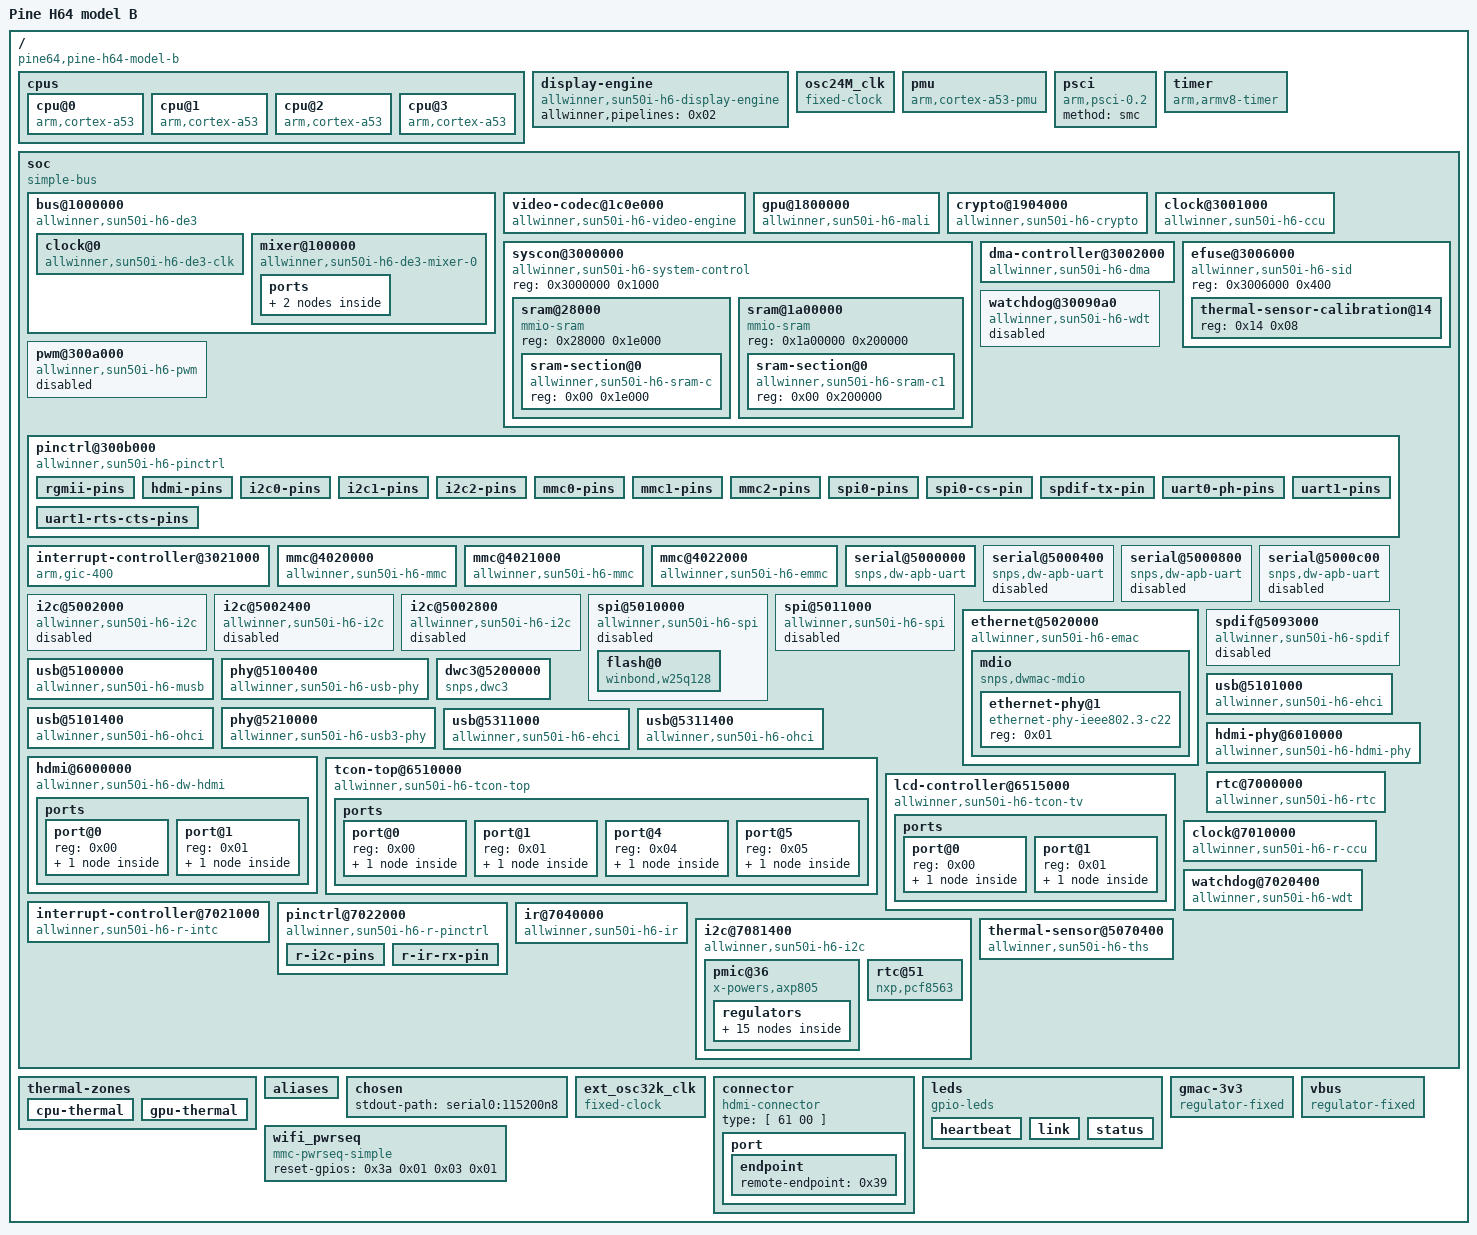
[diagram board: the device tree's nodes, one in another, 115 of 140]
/dts-v1/;

/ {
	interrupt-parent = < 0x01 >;
	#address-cells = < 0x01 >;
	#size-cells = < 0x01 >;
	model = "Pine H64 model B";
	compatible = "pine64,pine-h64-model-b\0allwinner,sun50i-h6";

	cpus {
		#address-cells = < 0x01 >;
		#size-cells = < 0x00 >;

		cpu@0 {
			compatible = "arm,cortex-a53";
			device_type = "cpu";
			reg = < 0x00 >;
			enable-method = "psci";
			phandle = < 0x03 >;
		};

		cpu@1 {
			compatible = "arm,cortex-a53";
			device_type = "cpu";
			reg = < 0x01 >;
			enable-method = "psci";
			phandle = < 0x04 >;
		};

		cpu@2 {
			compatible = "arm,cortex-a53";
			device_type = "cpu";
			reg = < 0x02 >;
			enable-method = "psci";
			phandle = < 0x05 >;
		};

		cpu@3 {
			compatible = "arm,cortex-a53";
			device_type = "cpu";
			reg = < 0x03 >;
			enable-method = "psci";
			phandle = < 0x06 >;
		};
	};

	display-engine {
		compatible = "allwinner,sun50i-h6-display-engine";
		allwinner,pipelines = < 0x02 >;
		status = "okay";
	};

	osc24M_clk {
		#clock-cells = < 0x00 >;
		compatible = "fixed-clock";
		clock-frequency = < 0x16e3600 >;
		clock-output-names = "osc24M";
		phandle = < 0x0d >;
	};

	pmu {
		compatible = "arm,cortex-a53-pmu";
		interrupts = < 0x00 0x8c 0x04 0x00 0x8d 0x04 0x00 0x8e 0x04 0x00 0x8f 0x04 >;
		interrupt-affinity = < 0x03 0x04 0x05 0x06 >;
	};

	psci {
		compatible = "arm,psci-0.2";
		method = "smc";
	};

	timer {
		compatible = "arm,armv8-timer";
		interrupts = < 0x01 0x0d 0xf04 0x01 0x0e 0xf04 0x01 0x0b 0xf04 0x01 0x0a 0xf04 >;
	};

	soc {
		compatible = "simple-bus";
		#address-cells = < 0x01 >;
		#size-cells = < 0x01 >;
		ranges;

		bus@1000000 {
			compatible = "allwinner,sun50i-h6-de3\0allwinner,sun50i-a64-de2";
			reg = < 0x1000000 0x400000 >;
			allwinner,sram = < 0x07 0x01 >;
			#address-cells = < 0x01 >;
			#size-cells = < 0x01 >;
			ranges = < 0x00 0x1000000 0x400000 >;

			clock@0 {
				compatible = "allwinner,sun50i-h6-de3-clk";
				reg = < 0x00 0x10000 >;
				clocks = < 0x08 0x1d 0x08 0x1e >;
				clock-names = "mod\0bus";
				resets = < 0x08 0x01 >;
				#clock-cells = < 0x01 >;
				#reset-cells = < 0x01 >;
				phandle = < 0x09 >;
			};

			mixer@100000 {
				compatible = "allwinner,sun50i-h6-de3-mixer-0";
				reg = < 0x100000 0x100000 >;
				clocks = < 0x09 0x00 0x09 0x06 >;
				clock-names = "bus\0mod";
				resets = < 0x09 0x00 >;
				phandle = < 0x02 >;

				ports {
					#address-cells = < 0x01 >;
					#size-cells = < 0x00 >;

					port@1 {
						reg = < 0x01 >;

						endpoint {
							remote-endpoint = < 0x0a >;
							phandle = < 0x2b >;
						};
					};
				};
			};
		};

		video-codec@1c0e000 {
			compatible = "allwinner,sun50i-h6-video-engine";
			reg = < 0x1c0e000 0x2000 >;
			clocks = < 0x08 0x26 0x08 0x25 0x08 0x36 >;
			clock-names = "ahb\0mod\0ram";
			resets = < 0x08 0x05 >;
			interrupts = < 0x00 0x59 0x04 >;
			allwinner,sram = < 0x0b 0x01 >;
		};

		gpu@1800000 {
			compatible = "allwinner,sun50i-h6-mali\0arm,mali-t720";
			reg = < 0x1800000 0x4000 >;
			interrupts = < 0x00 0x54 0x04 0x00 0x55 0x04 0x00 0x53 0x04 >;
			interrupt-names = "job\0mmu\0gpu";
			clocks = < 0x08 0x21 0x08 0x22 >;
			clock-names = "core\0bus";
			resets = < 0x08 0x03 >;
			status = "okay";
			mali-supply = < 0x0c >;
		};

		crypto@1904000 {
			compatible = "allwinner,sun50i-h6-crypto";
			reg = < 0x1904000 0x1000 >;
			interrupts = < 0x00 0x57 0x04 >;
			clocks = < 0x08 0x24 0x08 0x23 0x08 0x37 >;
			clock-names = "bus\0mod\0ram";
			resets = < 0x08 0x04 >;
		};

		syscon@3000000 {
			compatible = "allwinner,sun50i-h6-system-control\0allwinner,sun50i-a64-system-control";
			reg = < 0x3000000 0x1000 >;
			#address-cells = < 0x01 >;
			#size-cells = < 0x01 >;
			ranges;
			phandle = < 0x1f >;

			sram@28000 {
				compatible = "mmio-sram";
				reg = < 0x28000 0x1e000 >;
				#address-cells = < 0x01 >;
				#size-cells = < 0x01 >;
				ranges = < 0x00 0x28000 0x1e000 >;

				sram-section@0 {
					compatible = "allwinner,sun50i-h6-sram-c\0allwinner,sun50i-a64-sram-c";
					reg = < 0x00 0x1e000 >;
					phandle = < 0x07 >;
				};
			};

			sram@1a00000 {
				compatible = "mmio-sram";
				reg = < 0x1a00000 0x200000 >;
				#address-cells = < 0x01 >;
				#size-cells = < 0x01 >;
				ranges = < 0x00 0x1a00000 0x200000 >;

				sram-section@0 {
					compatible = "allwinner,sun50i-h6-sram-c1\0allwinner,sun4i-a10-sram-c1";
					reg = < 0x00 0x200000 >;
					phandle = < 0x0b >;
				};
			};
		};

		clock@3001000 {
			compatible = "allwinner,sun50i-h6-ccu";
			reg = < 0x3001000 0x1000 >;
			clocks = < 0x0d 0x0e 0x00 0x0e 0x02 >;
			clock-names = "hosc\0losc\0iosc";
			#clock-cells = < 0x01 >;
			#reset-cells = < 0x01 >;
			phandle = < 0x08 >;
		};

		dma-controller@3002000 {
			compatible = "allwinner,sun50i-h6-dma";
			reg = < 0x3002000 0x1000 >;
			interrupts = < 0x00 0x2b 0x04 >;
			clocks = < 0x08 0x2b 0x08 0x35 >;
			clock-names = "bus\0mbus";
			dma-channels = < 0x10 >;
			dma-requests = < 0x2e >;
			resets = < 0x08 0x08 >;
			#dma-cells = < 0x01 >;
			phandle = < 0x1c >;
		};

		efuse@3006000 {
			compatible = "allwinner,sun50i-h6-sid";
			reg = < 0x3006000 0x400 >;
			#address-cells = < 0x01 >;
			#size-cells = < 0x01 >;

			thermal-sensor-calibration@14 {
				reg = < 0x14 0x08 >;
				phandle = < 0x37 >;
			};
		};

		watchdog@30090a0 {
			compatible = "allwinner,sun50i-h6-wdt\0allwinner,sun6i-a31-wdt";
			reg = < 0x30090a0 0x20 >;
			interrupts = < 0x00 0x32 0x04 >;
			clocks = < 0x0d >;
			status = "disabled";
		};

		pwm@300a000 {
			compatible = "allwinner,sun50i-h6-pwm";
			reg = < 0x300a000 0x400 >;
			clocks = < 0x0d 0x08 0x32 >;
			clock-names = "mod\0bus";
			resets = < 0x08 0x0e >;
			#pwm-cells = < 0x03 >;
			status = "disabled";
		};

		pinctrl@300b000 {
			compatible = "allwinner,sun50i-h6-pinctrl";
			reg = < 0x300b000 0x400 >;
			interrupts = < 0x00 0x33 0x04 0x00 0x35 0x04 0x00 0x36 0x04 0x00 0x3b 0x04 >;
			clocks = < 0x08 0x1a 0x0d 0x0e 0x00 >;
			clock-names = "apb\0hosc\0losc";
			gpio-controller;
			#gpio-cells = < 0x03 >;
			interrupt-controller;
			#interrupt-cells = < 0x03 >;
			vcc-pc-supply = < 0x0f >;
			vcc-pd-supply = < 0x10 >;
			vcc-pg-supply = < 0x11 >;
			phandle = < 0x13 >;

			rgmii-pins {
				pins = "PD0\0PD1\0PD2\0PD3\0PD4\0PD5\0PD7\0PD8\0PD9\0PD10\0PD11\0PD12\0PD13\0PD19\0PD20";
				function = "emac";
				drive-strength = < 0x28 >;
				phandle = < 0x20 >;
			};

			hdmi-pins {
				pins = "PH8\0PH9\0PH10";
				function = "hdmi";
				phandle = < 0x28 >;
			};

			i2c0-pins {
				pins = "PD25\0PD26";
				function = "i2c0";
				phandle = < 0x19 >;
			};

			i2c1-pins {
				pins = "PH5\0PH6";
				function = "i2c1";
				phandle = < 0x1a >;
			};

			i2c2-pins {
				pins = "PD23\0PD24";
				function = "i2c2";
				phandle = < 0x1b >;
			};

			mmc0-pins {
				pins = "PF0\0PF1\0PF2\0PF3\0PF4\0PF5";
				function = "mmc0";
				drive-strength = < 0x1e >;
				bias-pull-up;
				phandle = < 0x12 >;
			};

			mmc1-pins {
				pins = "PG0\0PG1\0PG2\0PG3\0PG4\0PG5";
				function = "mmc1";
				drive-strength = < 0x1e >;
				bias-pull-up;
				phandle = < 0x14 >;
			};

			mmc2-pins {
				pins = "PC1\0PC4\0PC5\0PC6\0PC7\0PC8\0PC9\0PC10\0PC11\0PC12\0PC13\0PC14";
				function = "mmc2";
				drive-strength = < 0x1e >;
				bias-pull-up;
				phandle = < 0x17 >;
			};

			spi0-pins {
				pins = "PC0\0PC2\0PC3";
				function = "spi0";
				phandle = < 0x1d >;
			};

			spi0-cs-pin {
				pins = "PC5";
				function = "spi0";
				phandle = < 0x1e >;
			};

			spdif-tx-pin {
				pins = "PH7";
				function = "spdif";
				phandle = < 0x23 >;
			};

			uart0-ph-pins {
				pins = "PH0\0PH1";
				function = "uart0";
				phandle = < 0x18 >;
			};

			uart1-pins {
				pins = "PG6\0PG7";
				function = "uart1";
			};

			uart1-rts-cts-pins {
				pins = "PG8\0PG9";
				function = "uart1";
			};
		};

		interrupt-controller@3021000 {
			compatible = "arm,gic-400";
			reg = < 0x3021000 0x1000 0x3022000 0x2000 0x3024000 0x2000 0x3026000 0x2000 >;
			interrupts = < 0x01 0x09 0xf04 >;
			interrupt-controller;
			#interrupt-cells = < 0x03 >;
			phandle = < 0x01 >;
		};

		mmc@4020000 {
			compatible = "allwinner,sun50i-h6-mmc\0allwinner,sun50i-a64-mmc";
			reg = < 0x4020000 0x1000 >;
			clocks = < 0x08 0x43 0x08 0x40 >;
			clock-names = "ahb\0mmc";
			resets = < 0x08 0x12 >;
			reset-names = "ahb";
			interrupts = < 0x00 0x23 0x04 >;
			pinctrl-names = "default";
			pinctrl-0 = < 0x12 >;
			status = "okay";
			#address-cells = < 0x01 >;
			#size-cells = < 0x00 >;
			vmmc-supply = < 0x10 >;
			cd-gpios = < 0x13 0x05 0x06 0x01 >;
			bus-width = < 0x04 >;
		};

		mmc@4021000 {
			compatible = "allwinner,sun50i-h6-mmc\0allwinner,sun50i-a64-mmc";
			reg = < 0x4021000 0x1000 >;
			clocks = < 0x08 0x44 0x08 0x41 >;
			clock-names = "ahb\0mmc";
			resets = < 0x08 0x13 >;
			reset-names = "ahb";
			interrupts = < 0x00 0x24 0x04 >;
			pinctrl-names = "default";
			pinctrl-0 = < 0x14 >;
			status = "okay";
			#address-cells = < 0x01 >;
			#size-cells = < 0x00 >;
			vmmc-supply = < 0x15 >;
			vqmmc-supply = < 0x0f >;
			mmc-pwrseq = < 0x16 >;
			non-removable;
			bus-width = < 0x04 >;
		};

		mmc@4022000 {
			compatible = "allwinner,sun50i-h6-emmc\0allwinner,sun50i-a64-emmc";
			reg = < 0x4022000 0x1000 >;
			clocks = < 0x08 0x45 0x08 0x42 >;
			clock-names = "ahb\0mmc";
			resets = < 0x08 0x14 >;
			reset-names = "ahb";
			interrupts = < 0x00 0x25 0x04 >;
			pinctrl-names = "default";
			pinctrl-0 = < 0x17 >;
			mmc-hs200-1_8v;
			mmc-hs400-1_8v;
			mmc-hs400-enhanced-strobe;
			status = "okay";
			#address-cells = < 0x01 >;
			#size-cells = < 0x00 >;
			vmmc-supply = < 0x10 >;
			vqmmc-supply = < 0x0f >;
			non-removable;
			cap-mmc-hw-reset;
			bus-width = < 0x08 >;
		};

		serial@5000000 {
			compatible = "snps,dw-apb-uart";
			reg = < 0x5000000 0x400 >;
			interrupts = < 0x00 0x00 0x04 >;
			reg-shift = < 0x02 >;
			reg-io-width = < 0x04 >;
			clocks = < 0x08 0x46 >;
			resets = < 0x08 0x15 >;
			status = "okay";
			pinctrl-names = "default";
			pinctrl-0 = < 0x18 >;
		};

		serial@5000400 {
			compatible = "snps,dw-apb-uart";
			reg = < 0x5000400 0x400 >;
			interrupts = < 0x00 0x01 0x04 >;
			reg-shift = < 0x02 >;
			reg-io-width = < 0x04 >;
			clocks = < 0x08 0x47 >;
			resets = < 0x08 0x16 >;
			status = "disabled";
		};

		serial@5000800 {
			compatible = "snps,dw-apb-uart";
			reg = < 0x5000800 0x400 >;
			interrupts = < 0x00 0x02 0x04 >;
			reg-shift = < 0x02 >;
			reg-io-width = < 0x04 >;
			clocks = < 0x08 0x48 >;
			resets = < 0x08 0x17 >;
			status = "disabled";
		};

		serial@5000c00 {
			compatible = "snps,dw-apb-uart";
			reg = < 0x5000c00 0x400 >;
			interrupts = < 0x00 0x03 0x04 >;
			reg-shift = < 0x02 >;
			reg-io-width = < 0x04 >;
			clocks = < 0x08 0x49 >;
			resets = < 0x08 0x18 >;
			status = "disabled";
		};

		i2c@5002000 {
			compatible = "allwinner,sun50i-h6-i2c\0allwinner,sun6i-a31-i2c";
			reg = < 0x5002000 0x400 >;
			interrupts = < 0x00 0x04 0x04 >;
			clocks = < 0x08 0x4a >;
			resets = < 0x08 0x19 >;
			pinctrl-names = "default";
			pinctrl-0 = < 0x19 >;
			status = "disabled";
			#address-cells = < 0x01 >;
			#size-cells = < 0x00 >;
		};

		i2c@5002400 {
			compatible = "allwinner,sun50i-h6-i2c\0allwinner,sun6i-a31-i2c";
			reg = < 0x5002400 0x400 >;
			interrupts = < 0x00 0x05 0x04 >;
			clocks = < 0x08 0x4b >;
			resets = < 0x08 0x1a >;
			pinctrl-names = "default";
			pinctrl-0 = < 0x1a >;
			status = "disabled";
			#address-cells = < 0x01 >;
			#size-cells = < 0x00 >;
		};

		i2c@5002800 {
			compatible = "allwinner,sun50i-h6-i2c\0allwinner,sun6i-a31-i2c";
			reg = < 0x5002800 0x400 >;
			interrupts = < 0x00 0x06 0x04 >;
			clocks = < 0x08 0x4c >;
			resets = < 0x08 0x1b >;
			pinctrl-names = "default";
			pinctrl-0 = < 0x1b >;
			status = "disabled";
			#address-cells = < 0x01 >;
			#size-cells = < 0x00 >;
		};

		spi@5010000 {
			compatible = "allwinner,sun50i-h6-spi\0allwinner,sun8i-h3-spi";
			reg = < 0x5010000 0x1000 >;
			interrupts = < 0x00 0x0a 0x04 >;
			clocks = < 0x08 0x52 0x08 0x50 >;
			clock-names = "ahb\0mod";
			dmas = < 0x1c 0x16 0x1c 0x16 >;
			dma-names = "rx\0tx";
			resets = < 0x08 0x1f >;
			status = "disabled";
			#address-cells = < 0x01 >;
			#size-cells = < 0x00 >;
			pinctrl-0 = < 0x1d 0x1e >;
			pinctrl-names = "default";

			flash@0 {
				compatible = "winbond,w25q128\0jedec,spi-nor";
				reg = < 0x00 >;
				spi-max-frequency = < 0x3d0900 >;
			};
		};

		spi@5011000 {
			compatible = "allwinner,sun50i-h6-spi\0allwinner,sun8i-h3-spi";
			reg = < 0x5011000 0x1000 >;
			interrupts = < 0x00 0x0b 0x04 >;
			clocks = < 0x08 0x53 0x08 0x51 >;
			clock-names = "ahb\0mod";
			dmas = < 0x1c 0x17 0x1c 0x17 >;
			dma-names = "rx\0tx";
			resets = < 0x08 0x20 >;
			status = "disabled";
			#address-cells = < 0x01 >;
			#size-cells = < 0x00 >;
		};

		ethernet@5020000 {
			compatible = "allwinner,sun50i-h6-emac\0allwinner,sun50i-a64-emac";
			syscon = < 0x1f >;
			reg = < 0x5020000 0x10000 >;
			interrupts = < 0x00 0x0c 0x04 >;
			interrupt-names = "macirq";
			resets = < 0x08 0x21 >;
			reset-names = "stmmaceth";
			clocks = < 0x08 0x54 >;
			clock-names = "stmmaceth";
			status = "okay";
			pinctrl-names = "default";
			pinctrl-0 = < 0x20 >;
			phy-mode = "rgmii";
			phy-handle = < 0x21 >;
			phy-supply = < 0x22 >;
			allwinner,rx-delay-ps = < 0xc8 >;
			allwinner,tx-delay-ps = < 0xc8 >;

			mdio {
				compatible = "snps,dwmac-mdio";
				#address-cells = < 0x01 >;
				#size-cells = < 0x00 >;

				ethernet-phy@1 {
					compatible = "ethernet-phy-ieee802.3-c22";
					reg = < 0x01 >;
					phandle = < 0x21 >;
				};
			};
		};

		spdif@5093000 {
			#sound-dai-cells = < 0x00 >;
			compatible = "allwinner,sun50i-h6-spdif";
			reg = < 0x5093000 0x400 >;
			interrupts = < 0x00 0x15 0x04 >;
			clocks = < 0x08 0x63 0x08 0x62 >;
			clock-names = "apb\0spdif";
			resets = < 0x08 0x29 >;
			dmas = < 0x1c 0x02 >;
			dma-names = "tx";
			pinctrl-names = "default";
			pinctrl-0 = < 0x23 >;
			status = "disabled";
		};

		usb@5100000 {
			compatible = "allwinner,sun50i-h6-musb\0allwinner,sun8i-a33-musb";
			reg = < 0x5100000 0x400 >;
			clocks = < 0x08 0x74 >;
			resets = < 0x08 0x35 >;
			interrupts = < 0x00 0x17 0x04 >;
			interrupt-names = "mc";
			phys = < 0x24 0x00 >;
			phy-names = "usb";
			extcon = < 0x24 0x00 >;
			status = "okay";
			dr_mode = "host";
		};

		phy@5100400 {
			compatible = "allwinner,sun50i-h6-usb-phy";
			reg = < 0x5100400 0x24 0x5101800 0x04 0x5311800 0x04 >;
			reg-names = "phy_ctrl\0pmu0\0pmu3";
			clocks = < 0x08 0x69 0x08 0x6c >;
			clock-names = "usb0_phy\0usb3_phy";
			resets = < 0x08 0x2c 0x08 0x2e >;
			reset-names = "usb0_reset\0usb3_reset";
			status = "okay";
			#phy-cells = < 0x01 >;
			usb0_vbus-supply = < 0x25 >;
			usb3_vbus-supply = < 0x25 >;
			phandle = < 0x24 >;
		};

		usb@5101000 {
			compatible = "allwinner,sun50i-h6-ehci\0generic-ehci";
			reg = < 0x5101000 0x100 >;
			interrupts = < 0x00 0x18 0x04 >;
			clocks = < 0x08 0x6f 0x08 0x71 0x08 0x68 >;
			resets = < 0x08 0x30 0x08 0x32 >;
			status = "okay";
		};

		usb@5101400 {
			compatible = "allwinner,sun50i-h6-ohci\0generic-ohci";
			reg = < 0x5101400 0x100 >;
			interrupts = < 0x00 0x19 0x04 >;
			clocks = < 0x08 0x6f 0x08 0x68 >;
			resets = < 0x08 0x30 >;
			status = "okay";
		};

		dwc3@5200000 {
			compatible = "snps,dwc3";
			reg = < 0x5200000 0x10000 >;
			interrupts = < 0x00 0x1a 0x04 >;
			clocks = < 0x08 0x72 0x08 0x72 0x0e 0x00 >;
			clock-names = "ref\0bus_early\0suspend";
			resets = < 0x08 0x33 >;
			dr_mode = "host";
			phys = < 0x26 >;
			phy-names = "usb3-phy";
			status = "okay";
		};

		phy@5210000 {
			compatible = "allwinner,sun50i-h6-usb3-phy";
			reg = < 0x5210000 0x10000 >;
			clocks = < 0x08 0x6a >;
			resets = < 0x08 0x2d >;
			#phy-cells = < 0x00 >;
			status = "okay";
			phy-supply = < 0x25 >;
			phandle = < 0x26 >;
		};

		usb@5311000 {
			compatible = "allwinner,sun50i-h6-ehci\0generic-ehci";
			reg = < 0x5311000 0x100 >;
			interrupts = < 0x00 0x1c 0x04 >;
			clocks = < 0x08 0x70 0x08 0x73 0x08 0x6b >;
			resets = < 0x08 0x31 0x08 0x34 >;
			phys = < 0x24 0x03 >;
			phy-names = "usb";
			status = "okay";
		};

		usb@5311400 {
			compatible = "allwinner,sun50i-h6-ohci\0generic-ohci";
			reg = < 0x5311400 0x100 >;
			interrupts = < 0x00 0x1d 0x04 >;
			clocks = < 0x08 0x70 0x08 0x6b >;
			resets = < 0x08 0x31 >;
			phys = < 0x24 0x03 >;
			phy-names = "usb";
			status = "okay";
		};

		hdmi@6000000 {
			compatible = "allwinner,sun50i-h6-dw-hdmi";
			reg = < 0x6000000 0x10000 >;
			reg-io-width = < 0x01 >;
			interrupts = < 0x00 0x40 0x04 >;
			clocks = < 0x08 0x7e 0x08 0x7c 0x08 0x7b 0x08 0x7d 0x08 0x88 0x08 0x89 >;
			clock-names = "iahb\0isfr\0tmds\0cec\0hdcp\0hdcp-bus";
			resets = < 0x08 0x39 0x08 0x3e >;
			reset-names = "ctrl\0hdcp";
			phys = < 0x27 >;
			phy-names = "phy";
			pinctrl-names = "default";
			pinctrl-0 = < 0x28 >;
			status = "okay";

			ports {
				#address-cells = < 0x01 >;
				#size-cells = < 0x00 >;

				port@0 {
					reg = < 0x00 >;

					endpoint {
						remote-endpoint = < 0x29 >;
						phandle = < 0x2e >;
					};
				};

				port@1 {
					reg = < 0x01 >;

					endpoint {
						remote-endpoint = < 0x2a >;
						phandle = < 0x39 >;
					};
				};
			};
		};

		hdmi-phy@6010000 {
			compatible = "allwinner,sun50i-h6-hdmi-phy";
			reg = < 0x6010000 0x10000 >;
			clocks = < 0x08 0x7e 0x08 0x7c >;
			clock-names = "bus\0mod";
			resets = < 0x08 0x38 >;
			reset-names = "phy";
			#phy-cells = < 0x00 >;
			phandle = < 0x27 >;
		};

		tcon-top@6510000 {
			compatible = "allwinner,sun50i-h6-tcon-top";
			reg = < 0x6510000 0x1000 >;
			clocks = < 0x08 0x7f 0x08 0x82 >;
			clock-names = "bus\0tcon-tv0";
			clock-output-names = "tcon-top-tv0";
			resets = < 0x08 0x3a >;
			#clock-cells = < 0x01 >;
			phandle = < 0x2f >;

			ports {
				#address-cells = < 0x01 >;
				#size-cells = < 0x00 >;

				port@0 {
					#address-cells = < 0x01 >;
					#size-cells = < 0x00 >;
					reg = < 0x00 >;

					endpoint@0 {
						reg = < 0x00 >;
						remote-endpoint = < 0x2b >;
						phandle = < 0x0a >;
					};
				};

				port@1 {
					#address-cells = < 0x01 >;
					#size-cells = < 0x00 >;
					reg = < 0x01 >;

					endpoint@2 {
						reg = < 0x02 >;
						remote-endpoint = < 0x2c >;
						phandle = < 0x30 >;
					};
				};

				port@4 {
					#address-cells = < 0x01 >;
					#size-cells = < 0x00 >;
					reg = < 0x04 >;

					endpoint@0 {
						reg = < 0x00 >;
						remote-endpoint = < 0x2d >;
						phandle = < 0x31 >;
					};
				};

				port@5 {
					reg = < 0x05 >;

					endpoint {
						remote-endpoint = < 0x2e >;
						phandle = < 0x29 >;
					};
				};
			};
		};

		lcd-controller@6515000 {
			compatible = "allwinner,sun50i-h6-tcon-tv\0allwinner,sun8i-r40-tcon-tv";
			reg = < 0x6515000 0x1000 >;
			interrupts = < 0x00 0x42 0x04 >;
			clocks = < 0x08 0x83 0x2f 0x00 >;
			clock-names = "ahb\0tcon-ch1";
			resets = < 0x08 0x3c >;
			reset-names = "lcd";

			ports {
				#address-cells = < 0x01 >;
				#size-cells = < 0x00 >;

				port@0 {
					reg = < 0x00 >;

					endpoint {
						remote-endpoint = < 0x30 >;
						phandle = < 0x2c >;
					};
				};

				port@1 {
					#address-cells = < 0x01 >;
					#size-cells = < 0x00 >;
					reg = < 0x01 >;

					endpoint@1 {
						reg = < 0x01 >;
						remote-endpoint = < 0x31 >;
						phandle = < 0x2d >;
					};
				};
			};
		};

		rtc@7000000 {
			compatible = "allwinner,sun50i-h6-rtc";
			reg = < 0x7000000 0x400 >;
			interrupts = < 0x00 0x65 0x04 0x00 0x66 0x04 >;
			clock-output-names = "osc32k\0osc32k-out\0iosc";
			#clock-cells = < 0x01 >;
			clocks = < 0x32 >;
			phandle = < 0x0e >;
		};

		clock@7010000 {
			compatible = "allwinner,sun50i-h6-r-ccu";
			reg = < 0x7010000 0x400 >;
			clocks = < 0x0d 0x0e 0x00 0x0e 0x02 0x08 0x03 >;
			clock-names = "hosc\0losc\0iosc\0pll-periph";
			#clock-cells = < 0x01 >;
			#reset-cells = < 0x01 >;
			phandle = < 0x33 >;
		};

		watchdog@7020400 {
			compatible = "allwinner,sun50i-h6-wdt\0allwinner,sun6i-a31-wdt";
			reg = < 0x7020400 0x20 >;
			interrupts = < 0x00 0x67 0x04 >;
			clocks = < 0x0d >;
		};

		interrupt-controller@7021000 {
			compatible = "allwinner,sun50i-h6-r-intc\0allwinner,sun6i-a31-r-intc";
			interrupt-controller;
			#interrupt-cells = < 0x02 >;
			reg = < 0x7021000 0x400 >;
			interrupts = < 0x00 0x60 0x04 >;
			phandle = < 0x36 >;
		};

		pinctrl@7022000 {
			compatible = "allwinner,sun50i-h6-r-pinctrl";
			reg = < 0x7022000 0x400 >;
			interrupts = < 0x00 0x69 0x04 0x00 0x6f 0x04 >;
			clocks = < 0x33 0x02 0x0d 0x0e 0x00 >;
			clock-names = "apb\0hosc\0losc";
			gpio-controller;
			#gpio-cells = < 0x03 >;
			interrupt-controller;
			#interrupt-cells = < 0x03 >;
			vcc-pm-supply = < 0x11 >;
			phandle = < 0x3a >;

			r-i2c-pins {
				pins = "PL0\0PL1";
				function = "s_i2c";
				phandle = < 0x35 >;
			};

			r-ir-rx-pin {
				pins = "PL9";
				function = "s_cir_rx";
				phandle = < 0x34 >;
			};
		};

		ir@7040000 {
			compatible = "allwinner,sun50i-h6-ir\0allwinner,sun6i-a31-ir";
			reg = < 0x7040000 0x400 >;
			interrupts = < 0x00 0x6d 0x04 >;
			clocks = < 0x33 0x09 0x33 0x0b >;
			clock-names = "apb\0ir";
			resets = < 0x33 0x05 >;
			pinctrl-names = "default";
			pinctrl-0 = < 0x34 >;
			status = "okay";
		};

		i2c@7081400 {
			compatible = "allwinner,sun50i-h6-i2c\0allwinner,sun6i-a31-i2c";
			reg = < 0x7081400 0x400 >;
			interrupts = < 0x00 0x6b 0x04 >;
			clocks = < 0x33 0x08 >;
			resets = < 0x33 0x04 >;
			pinctrl-names = "default";
			pinctrl-0 = < 0x35 >;
			status = "okay";
			#address-cells = < 0x01 >;
			#size-cells = < 0x00 >;

			pmic@36 {
				compatible = "x-powers,axp805\0x-powers,axp806";
				reg = < 0x36 >;
				interrupt-parent = < 0x36 >;
				interrupts = < 0x00 0x08 >;
				interrupt-controller;
				#interrupt-cells = < 0x01 >;
				x-powers,self-working-mode;

				regulators {

					aldo1 {
						regulator-always-on;
						regulator-min-microvolt = < 0x325aa0 >;
						regulator-max-microvolt = < 0x325aa0 >;
						regulator-name = "vcc-pl";
						phandle = < 0x11 >;
					};

					aldo2 {
						regulator-min-microvolt = < 0x325aa0 >;
						regulator-max-microvolt = < 0x325aa0 >;
						regulator-name = "vcc-ac200";
						regulator-enable-ramp-delay = < 0x186a0 >;
						phandle = < 0x22 >;
					};

					aldo3 {
						regulator-always-on;
						regulator-min-microvolt = < 0x325aa0 >;
						regulator-max-microvolt = < 0x325aa0 >;
						regulator-name = "vcc-3v3-1";
					};

					bldo1 {
						regulator-always-on;
						regulator-min-microvolt = < 0x1b7740 >;
						regulator-max-microvolt = < 0x1b7740 >;
						regulator-name = "vcc-bias-pll";
					};

					bldo2 {
						regulator-always-on;
						regulator-min-microvolt = < 0x1b7740 >;
						regulator-max-microvolt = < 0x1b7740 >;
						regulator-name = "vcc-efuse-pcie-hdmi-io";
						phandle = < 0x0f >;
					};

					bldo3 {
						regulator-always-on;
						regulator-min-microvolt = < 0x1b7740 >;
						regulator-max-microvolt = < 0x1b7740 >;
						regulator-name = "vcc-dcxoio";
					};

					bldo4 {
					};

					cldo1 {
						regulator-always-on;
						regulator-min-microvolt = < 0x325aa0 >;
						regulator-max-microvolt = < 0x325aa0 >;
						regulator-name = "vcc-3v3-2";
						phandle = < 0x10 >;
					};

					cldo2 {
						regulator-min-microvolt = < 0x325aa0 >;
						regulator-max-microvolt = < 0x325aa0 >;
						regulator-name = "vcc-wifi-1";
						phandle = < 0x15 >;
					};

					cldo3 {
						regulator-min-microvolt = < 0x325aa0 >;
						regulator-max-microvolt = < 0x325aa0 >;
						regulator-name = "vcc-wifi-2";
					};

					dcdca {
						regulator-always-on;
						regulator-min-microvolt = < 0xc5c10 >;
						regulator-max-microvolt = < 0x107ac0 >;
						regulator-name = "vdd-cpu";
					};

					dcdcc {
						regulator-enable-ramp-delay = < 0x7d00 >;
						regulator-min-microvolt = < 0xc5c10 >;
						regulator-max-microvolt = < 0x107ac0 >;
						regulator-name = "vdd-gpu";
						phandle = < 0x0c >;
					};

					dcdcd {
						regulator-always-on;
						regulator-min-microvolt = < 0xea600 >;
						regulator-max-microvolt = < 0xea600 >;
						regulator-name = "vdd-sys";
					};

					dcdce {
						regulator-always-on;
						regulator-min-microvolt = < 0x124f80 >;
						regulator-max-microvolt = < 0x124f80 >;
						regulator-name = "vcc-dram";
					};

					sw {
					};
				};
			};

			rtc@51 {
				compatible = "nxp,pcf8563";
				reg = < 0x51 >;
				interrupt-parent = < 0x36 >;
				interrupts = < 0x00 0x08 >;
				#clock-cells = < 0x00 >;
			};
		};

		thermal-sensor@5070400 {
			compatible = "allwinner,sun50i-h6-ths";
			reg = < 0x5070400 0x100 >;
			interrupts = < 0x00 0x0f 0x04 >;
			clocks = < 0x08 0x59 >;
			clock-names = "bus";
			resets = < 0x08 0x24 >;
			nvmem-cells = < 0x37 >;
			nvmem-cell-names = "calibration";
			#thermal-sensor-cells = < 0x01 >;
			phandle = < 0x38 >;
		};
	};

	thermal-zones {

		cpu-thermal {
			polling-delay-passive = < 0x00 >;
			polling-delay = < 0x00 >;
			thermal-sensors = < 0x38 0x00 >;
		};

		gpu-thermal {
			polling-delay-passive = < 0x00 >;
			polling-delay = < 0x00 >;
			thermal-sensors = < 0x38 0x01 >;
		};
	};

	aliases {
		ethernet0 = "/soc/ethernet@5020000";
		serial0 = "/soc/serial@5000000";
		spi0 = "/soc/spi@5010000";
	};

	chosen {
		stdout-path = "serial0:115200n8";
	};

	ext_osc32k_clk {
		#clock-cells = < 0x00 >;
		compatible = "fixed-clock";
		clock-frequency = < 0x8000 >;
		clock-output-names = "ext_osc32k";
		phandle = < 0x32 >;
	};

	connector {
		compatible = "hdmi-connector";
		type = [ 61 00 ];

		port {

			endpoint {
				remote-endpoint = < 0x39 >;
				phandle = < 0x2a >;
			};
		};
	};

	leds {
		compatible = "gpio-leds";

		heartbeat {
			label = "pine-h64:green:heartbeat";
			gpios = < 0x3a 0x00 0x04 0x00 >;
		};

		link {
			label = "pine-h64:white:link";
			gpios = < 0x3a 0x00 0x03 0x00 >;
		};

		status {
			label = "pine-h64:blue:status";
			gpios = < 0x3a 0x00 0x07 0x00 >;
		};
	};

	gmac-3v3 {
		compatible = "regulator-fixed";
		regulator-name = "vcc-gmac-3v3";
		regulator-min-microvolt = < 0x325aa0 >;
		regulator-max-microvolt = < 0x325aa0 >;
		startup-delay-us = < 0x186a0 >;
		gpio = < 0x13 0x02 0x10 0x00 >;
		enable-active-high;
	};

	vbus {
		compatible = "regulator-fixed";
		regulator-name = "usb-vbus";
		regulator-min-microvolt = < 0x4c4b40 >;
		regulator-max-microvolt = < 0x4c4b40 >;
		startup-delay-us = < 0x186a0 >;
		gpio = < 0x3a 0x00 0x05 0x00 >;
		enable-active-high;
		phandle = < 0x25 >;
	};

	wifi_pwrseq {
		compatible = "mmc-pwrseq-simple";
		reset-gpios = < 0x3a 0x01 0x03 0x01 >;
		phandle = < 0x16 >;
	};
};
